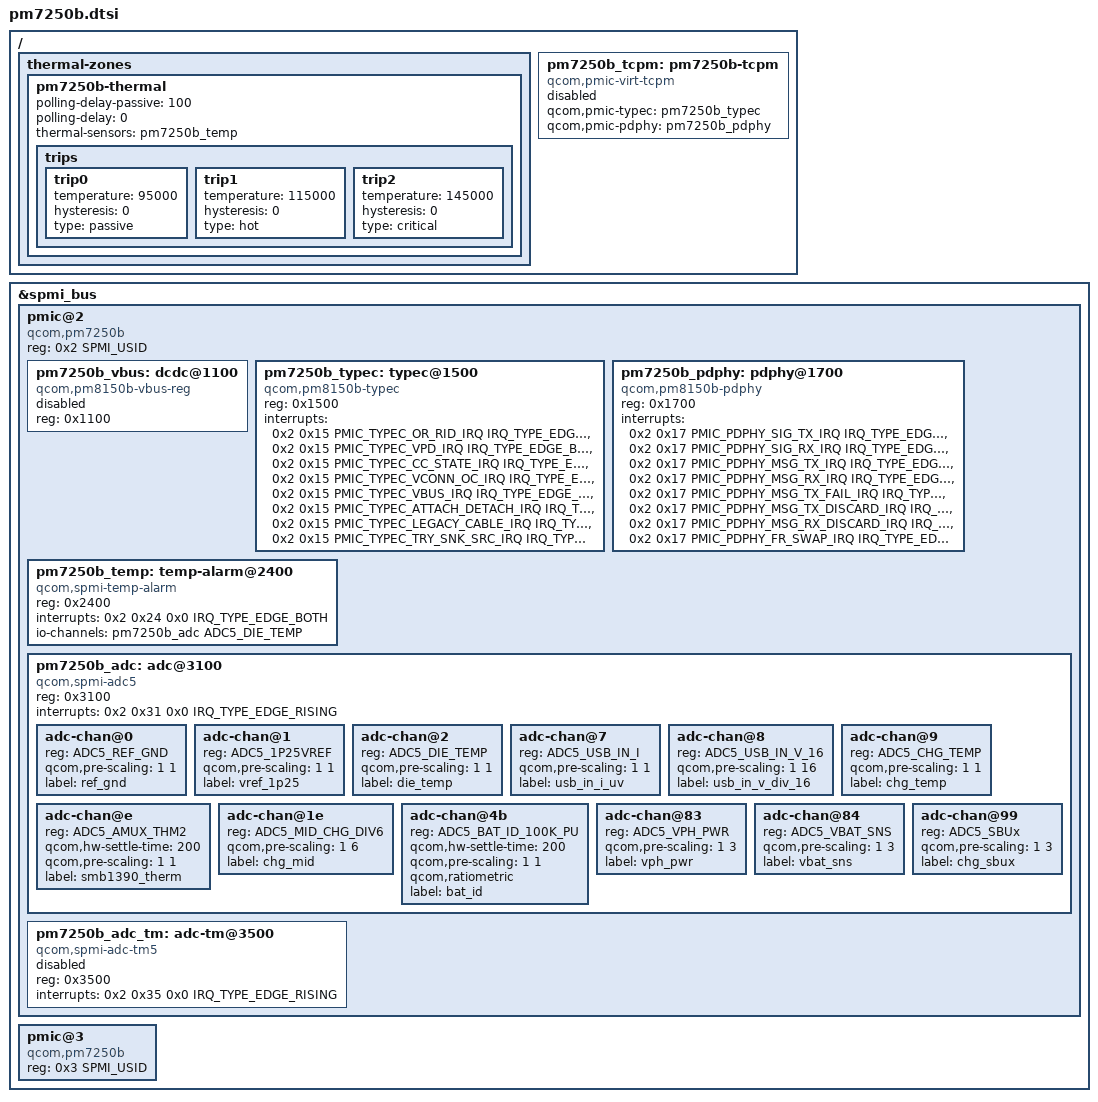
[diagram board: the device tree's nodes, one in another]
// SPDX-License-Identifier: BSD-3-Clause
/*
 * Copyright (C) 2022 Luca Weiss <luca.weiss@fairphone.com>
 */

#include <dt-bindings/interrupt-controller/irq.h>
#include <dt-bindings/spmi/spmi.h>
#include <dt-bindings/usb/typec/qcom,pmic-pdphy.h>
#include <dt-bindings/usb/typec/qcom,pmic-typec.h>

/ {
	thermal-zones {
		pm7250b-thermal {
			polling-delay-passive = <100>;
			polling-delay = <0>;

			thermal-sensors = <&pm7250b_temp>;

			trips {
				trip0 {
					temperature = <95000>;
					hysteresis = <0>;
					type = "passive";
				};

				trip1 {
					temperature = <115000>;
					hysteresis = <0>;
					type = "hot";
				};

				trip2 {
					temperature = <145000>;
					hysteresis = <0>;
					type = "critical";
				};
			};
		};
	};

	pm7250b_tcpm: pm7250b-tcpm {
		compatible = "qcom,pmic-virt-tcpm";
		qcom,pmic-typec = <&pm7250b_typec>;
		qcom,pmic-pdphy = <&pm7250b_pdphy>;

		status = "disabled";
	};
};

&spmi_bus {
	pmic@2 {
		compatible = "qcom,pm7250b", "qcom,spmi-pmic";
		reg = <0x2 SPMI_USID>;
		#address-cells = <1>;
		#size-cells = <0>;

		pm7250b_vbus: dcdc@1100 {
			compatible = "qcom,pm8150b-vbus-reg";
			status = "disabled";
			reg = <0x1100>;
		};

		pm7250b_typec: typec@1500 {
			compatible = "qcom,pm8150b-typec";
			reg = <0x1500>;
			interrupts = <0x2 0x15 PMIC_TYPEC_OR_RID_IRQ
				      IRQ_TYPE_EDGE_RISING>,
				     <0x2 0x15 PMIC_TYPEC_VPD_IRQ
				      IRQ_TYPE_EDGE_BOTH>,
				     <0x2 0x15 PMIC_TYPEC_CC_STATE_IRQ
				      IRQ_TYPE_EDGE_RISING>,
				     <0x2 0x15 PMIC_TYPEC_VCONN_OC_IRQ
				      IRQ_TYPE_EDGE_BOTH>,
				     <0x2 0x15 PMIC_TYPEC_VBUS_IRQ
				      IRQ_TYPE_EDGE_RISING>,
				     <0x2 0x15 PMIC_TYPEC_ATTACH_DETACH_IRQ
				      IRQ_TYPE_EDGE_RISING>,
				     <0x2 0x15 PMIC_TYPEC_LEGACY_CABLE_IRQ
				      IRQ_TYPE_EDGE_BOTH>,
				     <0x2 0x15 PMIC_TYPEC_TRY_SNK_SRC_IRQ
				      IRQ_TYPE_EDGE_RISING>;
			interrupt-names = "or-rid-detect-change",
					  "vpd-detect",
					  "cc-state-change",
					  "vconn-oc",
					  "vbus-change",
					  "attach-detach",
					  "legacy-cable-detect",
					  "try-snk-src-detect";
			//status = "disabled";
		};

		pm7250b_pdphy: pdphy@1700 {
			compatible = "qcom,pm8150b-pdphy";
			reg = <0x1700>;
			interrupts = <0x2 0x17 PMIC_PDPHY_SIG_TX_IRQ
				      IRQ_TYPE_EDGE_RISING>,
				     <0x2 0x17 PMIC_PDPHY_SIG_RX_IRQ
				      IRQ_TYPE_EDGE_RISING>,
				     <0x2 0x17 PMIC_PDPHY_MSG_TX_IRQ
				      IRQ_TYPE_EDGE_RISING>,
				     <0x2 0x17 PMIC_PDPHY_MSG_RX_IRQ
				      IRQ_TYPE_EDGE_RISING>,
				     <0x2 0x17 PMIC_PDPHY_MSG_TX_FAIL_IRQ
				      IRQ_TYPE_EDGE_RISING>,
				     <0x2 0x17 PMIC_PDPHY_MSG_TX_DISCARD_IRQ
				      IRQ_TYPE_EDGE_RISING>,
				     <0x2 0x17 PMIC_PDPHY_MSG_RX_DISCARD_IRQ
				      IRQ_TYPE_EDGE_RISING>,
				     <0x2 0x17 PMIC_PDPHY_FR_SWAP_IRQ
				      IRQ_TYPE_EDGE_RISING>;
			interrupt-names = "sig-tx",
					  "sig-rx",
					  "msg-tx",
					  "msg-rx",
					  "msg-tx-failed",
					  "msg-tx-discarded",
					  "msg-rx-discarded",
					  "fr-swap";
			//status = "disabled";
		};

		pm7250b_temp: temp-alarm@2400 {
			compatible = "qcom,spmi-temp-alarm";
			reg = <0x2400>;
			interrupts = <0x2 0x24 0x0 IRQ_TYPE_EDGE_BOTH>;
			io-channels = <&pm7250b_adc ADC5_DIE_TEMP>;
			io-channel-names = "thermal";
			#thermal-sensor-cells = <0>;
		};

		pm7250b_adc: adc@3100 {
			compatible = "qcom,spmi-adc5";
			reg = <0x3100>;
			#address-cells = <1>;
			#size-cells = <0>;
			#io-channel-cells = <1>;
			interrupts = <0x2 0x31 0x0 IRQ_TYPE_EDGE_RISING>;

			adc-chan@0 {
				reg = <ADC5_REF_GND>;
				qcom,pre-scaling = <1 1>;
				label = "ref_gnd";
			};

			adc-chan@1 {
				reg = <ADC5_1P25VREF>;
				qcom,pre-scaling = <1 1>;
				label = "vref_1p25";
			};

			adc-chan@2 {
				reg = <ADC5_DIE_TEMP>;
				qcom,pre-scaling = <1 1>;
				label = "die_temp";
			};

			adc-chan@7 {
				reg = <ADC5_USB_IN_I>;
				qcom,pre-scaling = <1 1>;
				label = "usb_in_i_uv";
			};

			adc-chan@8 {
				reg = <ADC5_USB_IN_V_16>;
				qcom,pre-scaling = <1 16>;
				label = "usb_in_v_div_16";
			};

			adc-chan@9 {
				reg = <ADC5_CHG_TEMP>;
				qcom,pre-scaling = <1 1>;
				label = "chg_temp";
			};

			adc-chan@e {
				reg = <ADC5_AMUX_THM2>;
				qcom,hw-settle-time = <200>;
				qcom,pre-scaling = <1 1>;
				label = "smb1390_therm";
			};

			adc-chan@1e {
				reg = <ADC5_MID_CHG_DIV6>;
				qcom,pre-scaling = <1 6>;
				label = "chg_mid";
			};

			// adc-chan@2a {
			// 	reg = <ADC5_BAT_THERM_30K_PU>;
			// 	qcom,ratiometric;
			// 	qcom,hw-settle-time = <200>;
			// 	qcom,pre-scaling = <1 1>;
			// 	label = "bat_therm_30k";
			// };

			// adc-chan@4a {
			// 	reg = <ADC5_BAT_THERM_100K_PU>;
			// 	qcom,ratiometric;
			// 	qcom,hw-settle-time = <200>;
			// 	qcom,pre-scaling = <1 1>;
			// 	label = "bat_therm";
			// };

			adc-chan@4b {
				reg = <ADC5_BAT_ID_100K_PU>;
				qcom,hw-settle-time = <200>;
				qcom,pre-scaling = <1 1>;
				qcom,ratiometric;
				label = "bat_id";
			};

			// adc-chan@6a {
			// 	reg = <ADC5_BAT_THERM_400K_PU>;
			// 	qcom,ratiometric;
			// 	qcom,hw-settle-time = <200>;
			// 	qcom,pre-scaling = <1 1>;
			// 	label = "bat_therm_400k";
			// };

			adc-chan@83 {
				reg = <ADC5_VPH_PWR>;
				qcom,pre-scaling = <1 3>;
				label = "vph_pwr";
			};

			adc-chan@84 {
				reg = <ADC5_VBAT_SNS>;
				qcom,pre-scaling = <1 3>;
				label = "vbat_sns";
			};

			adc-chan@99 {
				reg = <ADC5_SBUx>;
				qcom,pre-scaling = <1 3>;
				label = "chg_sbux";
			};

			// adc-chan@b0 {
			// 	reg = <ADC5_INT_EXT_ISENSE_VBAT_VDATA>;
			// 	qcom,pre-scaling = <1 1>;
			// 	label = "v_i_int_vbat_vdata";
			// };

			// adc-chan@b4 {
			// 	reg = <ADC5_PARALLEL_ISENSE_VBAT_VDATA>;
			// 	qcom,pre-scaling = <1 1>;
			// 	label = "v_i_parallel_vbat_vdata";
			// };
		};

		pm7250b_adc_tm: adc-tm@3500 {
			compatible = "qcom,spmi-adc-tm5";
			reg = <0x3500>;
			interrupts = <0x2 0x35 0x0 IRQ_TYPE_EDGE_RISING>;
			#thermal-sensor-cells = <1>;
			#address-cells = <1>;
			#size-cells = <0>;
			status = "disabled";
		};
	};

	pmic@3 {
		compatible = "qcom,pm7250b", "qcom,spmi-pmic";
		reg = <0x3 SPMI_USID>;
		#address-cells = <1>;
		#size-cells = <0>;
	};
};
